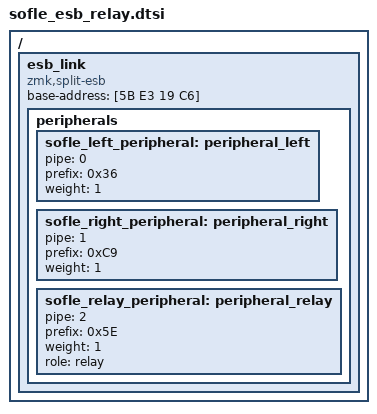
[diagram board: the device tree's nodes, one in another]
/ {
    esb_link {
        compatible = "zmk,split-esb";
        base-address = [5B E3 19 C6];
        peripherals {
            sofle_left_peripheral: peripheral_left {
                pipe = <0>;
                prefix = <0x36>;
                weight = <1>;
            };
            sofle_right_peripheral: peripheral_right {
                pipe = <1>;
                prefix = <0xC9>;
                weight = <1>;
            };
            sofle_relay_peripheral: peripheral_relay {
                pipe = <2>;
                prefix = <0x5E>;
                weight = <1>;
                role = "relay";
            };
        };
    };
};
